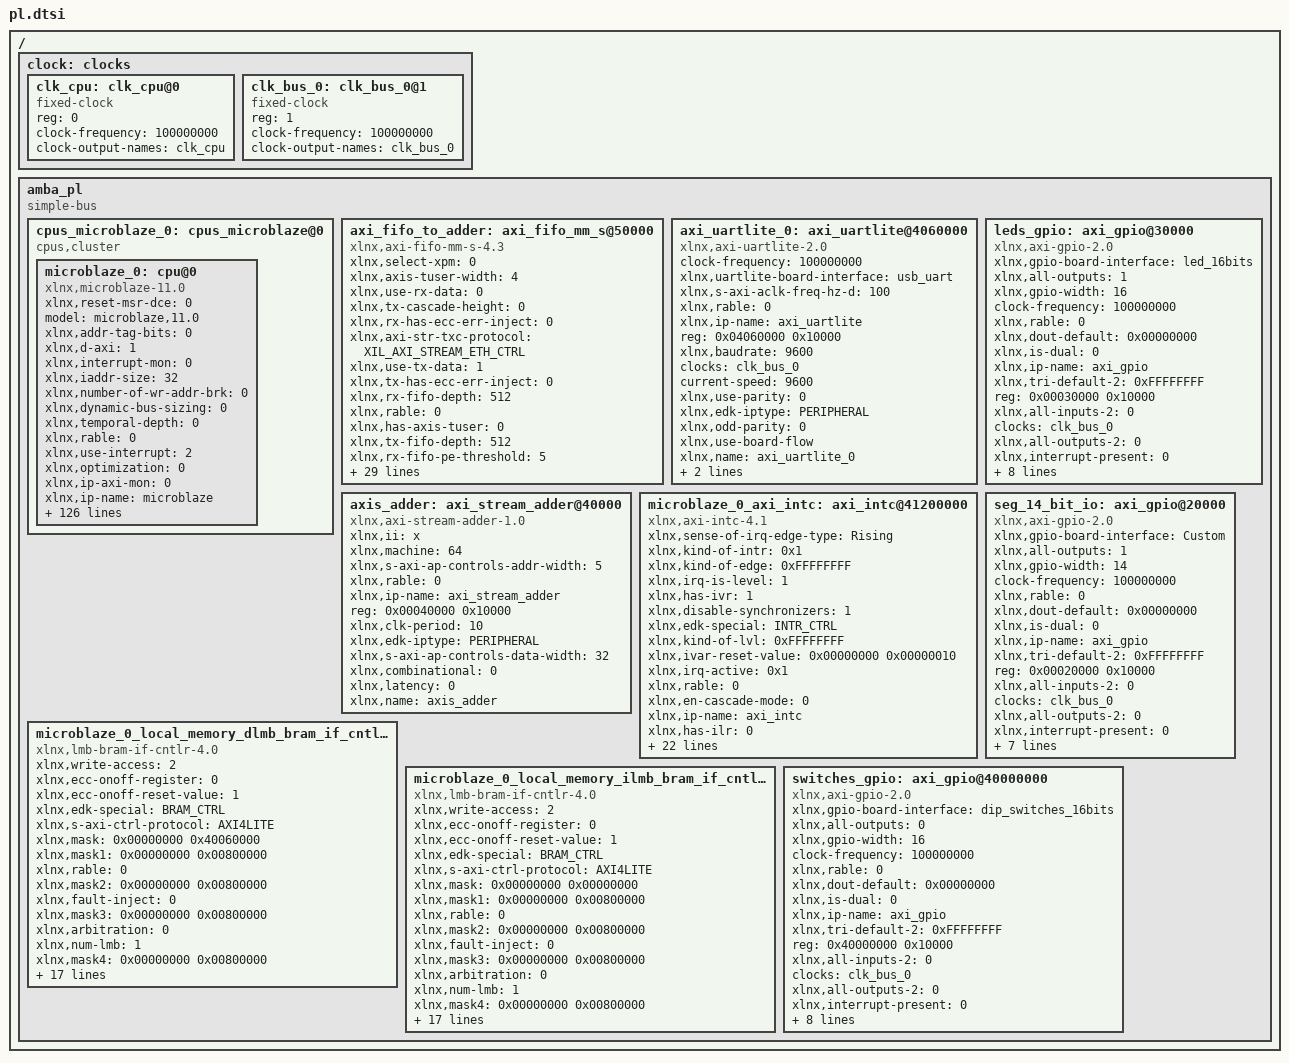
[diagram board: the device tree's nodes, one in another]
/ {
	clock: clocks {
		#address-cells = <1>;
		#size-cells = <0>;
		clk_cpu: clk_cpu@0 {
			compatible = "fixed-clock";
			reg = <0>;
			clock-frequency = <100000000>;
			clock-output-names = "clk_cpu";
			#clock-cells = <0>;
		};
		clk_bus_0: clk_bus_0@1 {
			compatible = "fixed-clock";
			reg = <1>;
			clock-frequency = <100000000>;
			clock-output-names = "clk_bus_0";
			#clock-cells = <0>;
		};
	};
	amba_pl: amba_pl {
		ranges;
		compatible = "simple-bus";
		#address-cells = <1>;
		#size-cells = <1>;
		cpus_microblaze_0: cpus_microblaze@0 {
			#cpu-mask-cells = <1>;
			compatible = "cpus,cluster";
			microblaze_0: cpu@0 {
				xlnx,reset-msr-dce = <0>;
				model = "microblaze,11.0";
				xlnx,addr-tag-bits = <0>;
				xlnx,d-axi = <1>;
				xlnx,interrupt-mon = <0>;
				xlnx,iaddr-size = <32>;
				xlnx,number-of-wr-addr-brk = <0>;
				xlnx,dynamic-bus-sizing = <0>;
				xlnx,temporal-depth = <0>;
				xlnx,rable = <0>;
				xlnx,use-interrupt = <2>;
				xlnx,optimization = <0>;
				xlnx,ip-axi-mon = <0>;
				xlnx,ip-name = "microblaze";
				d-cache-highaddr = <0x3fffffff>;
				xlnx,dcache-force-tag-lutram = <0>;
				xlnx,pc-width = <32>;
				xlnx,interrupt-is-edge = <0>;
				reg = <0x0>;
				xlnx,async-interrupt = <1>;
				xlnx,use-mmu = <0>;
				xlnx,reset-msr-ee = <0>;
				xlnx,icache-victims = <0>;
				xlnx,use-reorder-instr = <1>;
				xlnx,d-lmb-mon = <0>;
				xlnx,d-lmb-protocol = <0>;
				xlnx,ill-opcode-exception = <0>;
				xlnx,dcache-always-used = <1>;
				xlnx,use-div = <0>;
				xlnx,dc-axi-mon = <0>;
				xlnx,debug-trace-async-reset = <0>;
				xlnx,trace = <0>;
				xlnx,part = "xc7a35tcpg236-1";
				i-cache-baseaddr = <0x00000000>;
				xlnx,use-config-reset = <0>;
				xlnx,pvr = <0>;
				xlnx,i-lmb-mon = <0>;
				xlnx,dcache-byte-size = <8192>;
				xlnx,fault-tolerant = <0>;
				xlnx,family = "artix7";
				compatible = "xlnx,microblaze-11.0" , "xlnx,microblaze";
				xlnx,data-size = <32>;
				xlnx,mmu-zones = <16>;
				xlnx,debug-trace-size = <8192>;
				xlnx,mmu-privileged-instr = <0>;
				xlnx,enable-discrete-ports = <0>;
				d-cache-line-size = <16>;
				xlnx,d-lmb = <1>;
				xlnx,sco = <0>;
				xlnx,reset-msr-eip = <0>;
				clock-frequency = <100000000>;
				xlnx,debug-interface = <0>;
				xlnx,use-ext-brk = <0>;
				xlnx,daddr-size = <32>;
				xlnx,debug-enabled = <1>;
				xlnx,reset-msr-ice = <0>;
				xlnx,num-sync-ff-dbg-trace-clk = <2>;
				xlnx,i-lmb-protocol = <0>;
				xlnx,endianness = <1>;
				xlnx,fsl-exception = <0>;
				i-cache-line-size = <16>;
				xlnx,use-extended-fsl-instr = <0>;
				xlnx,reset-msr = <0x00000000>;
				xlnx,dp-axi-mon = <0>;
				xlnx,branch-target-cache-size = <0>;
				xlnx,dcache-use-writeback = <0>;
				xlnx,div-zero-exception = <0>;
				xlnx,mmu-tlb-access = <3>;
				bus-handle = <&amba_pl>;
				xlnx,cache-byte-size = <8192>;
				xlnx,pvr-user2 = <0x00000000>;
				xlnx,opcode-0x0-illegal = <0>;
				xlnx,icache-line-len = <4>;
				xlnx,ecc-use-ce-exception = <0>;
				xlnx,base-vectors = <0x00000000 0x00000000>;
				xlnx,use-dcache = <0>;
				xlnx,use-barrel = <0>;
				xlnx,reset-msr-bip = <0>;
				xlnx,edk-special = "microblaze";
				xlnx,allow-dcache-wr = <1>;
				xlnx,addr-size = <32>;
				xlnx,debug-external-trace = <0>;
				xlnx,piaddr-size = <32>;
				i-cache-highaddr = <0x3fffffff>;
				xlnx,num-sync-ff-clk-debug = <2>;
				xlnx,debug-event-counters = <5>;
				xlnx,fpu-exception = <0>;
				xlnx,allow-icache-wr = <1>;
				xlnx,i-axi = <0>;
				xlnx,g-use-exceptions = <0>;
				xlnx,icache-streams = <0>;
				xlnx,g-template-list = <0>;
				xlnx,dcache-line-len = <4>;
				xlnx,num-sync-ff-clk = <2>;
				xlnx,use-stack-protection = <0>;
				xlnx,use-hw-mul = <0>;
				xlnx,num-sync-ff-dbg-clk = <1>;
				xlnx,interconnect = <2>;
				xlnx,edk-iptype = "PROCESSOR";
				xlnx,debug-latency-counters = <1>;
				i-cache-size = <8192>;
				xlnx,use-fpu = <0>;
				xlnx,reset-msr-ie = <0>;
				xlnx,edge-is-positive = <1>;
				xlnx,use-pcmp-instr = <0>;
				xlnx,use-icache = <0>;
				d-cache-size = <8192>;
				xlnx,async-wakeup = <3>;
				xlnx,use-non-secure = <0>;
				xlnx,dcache-addr-tag = <0>;
				xlnx,number-of-rd-addr-brk = <0>;
				d-cache-baseaddr = <0x00000000>;
				xlnx,area-optimized = <0>;
				xlnx,avoid-primitives = <0>;
				xlnx,lockstep-slave = <0>;
				xlnx,use-ext-nm-brk = <0>;
				xlnx,instr-size = <32>;
				interrupt-handle = <&microblaze_0_axi_intc>;
				xlnx,icache-always-used = <1>;
				xlnx,i-lmb = <1>;
				xlnx,mmu-dtlb-size = <4>;
				xlnx,lockstep-select = <0>;
				xlnx,lmb-data-size = <32>;
				xlnx,ic-axi-mon = <0>;
				xlnx,num-sync-ff-clk-irq = <1>;
				xlnx,fsl-links = <0>;
				timebase-frequency = <100000000>;
				xlnx,icache-force-tag-lutram = <0>;
				xlnx,dcache-data-width = <0>;
				xlnx,dcache-victims = <0>;
				xlnx,use-branch-target-cache = <0>;
				xlnx,debug-profile-size = <0>;
				xlnx,unaligned-exceptions = <0>;
				xlnx,lockstep-master = <0>;
				xlnx,freq = <100000000>;
				xlnx,number-of-pc-brk = <1>;
				xlnx,mmu-itlb-size = <2>;
				xlnx,imprecise-exceptions = <0>;
				xlnx,use-msr-instr = <0>;
				xlnx,icache-data-width = <0>;
				xlnx,debug-counter-width = <32>;
			};
		};
		axi_fifo_to_adder: axi_fifo_mm_s@50000 {
			xlnx,select-xpm = <0>;
			xlnx,axis-tuser-width = <4>;
			compatible = "xlnx,axi-fifo-mm-s-4.3";
			xlnx,use-rx-data = <0>;
			xlnx,tx-cascade-height = <0>;
			xlnx,rx-has-ecc-err-inject = <0>;
			xlnx,axi-str-txc-protocol = "XIL_AXI_STREAM_ETH_CTRL";
			xlnx,use-tx-data = <1>;
			xlnx,tx-has-ecc-err-inject = <0>;
			xlnx,rx-fifo-depth = <512>;
			xlnx,rable = <0>;
			xlnx,has-axis-tuser = <0>;
			xlnx,tx-fifo-depth = <512>;
			xlnx,rx-fifo-pe-threshold = <5>;
			xlnx,data-interface-type = <0>;
			xlnx,ip-name = "axi_fifo_mm_s";
			xlnx,use-tx-ctrl = <0>;
			xlnx,rx-fifo-pf-threshold = <507>;
			xlnx,axis-tid-width = <4>;
			reg = <0x00050000 0x1000>;
			xlnx,tx-fifo-pe-threshold = <5>;
			xlnx,tx-fifo-pf-threshold = <507>;
			xlnx,s-axi4-data-width = <32>;
			xlnx,has-axis-tstrb = <0>;
			xlnx,axi-str-rxd-protocol = "XIL_AXI_STREAM_ETH_DATA";
			xlnx,use-rx-cut-through = <0>;
			xlnx,axi-str-rxd-tdata-width = <32>;
			xlnx,axis-tdest-width = <4>;
			xlnx,has-axis-tkeep = <0>;
			xlnx,has-axis-tid = <0>;
			xlnx,edk-iptype = "PERIPHERAL";
			xlnx,axi-str-txc-tdata-width = <32>;
			xlnx,axi-str-txd-protocol = "XIL_AXI_STREAM_ETH_DATA";
			xlnx,use-tx-cut-through = <0>;
			xlnx,axi-str-txd-tdata-width = <32>;
			xlnx,rx-enable-ecc = <0>;
			status = "okay";
			xlnx,has-axis-tdest = <0>;
			xlnx,tx-enable-ecc = <0>;
			xlnx,s-axi-id-width = <4>;
			xlnx,rx-cascade-height = <0>;
			xlnx,name = "axi_fifo_to_adder";
		};
		axi_uartlite_0: axi_uartlite@4060000 {
			compatible = "xlnx,axi-uartlite-2.0" , "xlnx,xps-uartlite-1.00.a";
			clock-frequency = <100000000>;
			xlnx,uartlite-board-interface = "usb_uart";
			xlnx,s-axi-aclk-freq-hz-d = <100>;
			xlnx,rable = <0>;
			xlnx,ip-name = "axi_uartlite";
			reg = <0x04060000 0x10000>;
			xlnx,baudrate = <9600>;
			clocks = <&clk_bus_0>;
			current-speed = <9600>;
			xlnx,use-parity = <0>;
			xlnx,edk-iptype = "PERIPHERAL";
			xlnx,odd-parity = <0>;
			status = "okay";
			xlnx,use-board-flow;
			xlnx,name = "axi_uartlite_0";
			xlnx,data-bits = <8>;
			xlnx,parity = "No_Parity";
		};
		axis_adder: axi_stream_adder@40000 {
			compatible = "xlnx,axi-stream-adder-1.0";
			xlnx,ii = "x";
			xlnx,machine = <64>;
			xlnx,s-axi-ap-controls-addr-width = <5>;
			xlnx,rable = <0>;
			xlnx,ip-name = "axi_stream_adder";
			reg = <0x00040000 0x10000>;
			xlnx,clk-period = <10>;
			xlnx,edk-iptype = "PERIPHERAL";
			xlnx,s-axi-ap-controls-data-width = <32>;
			status = "okay";
			xlnx,combinational = <0>;
			xlnx,latency = <0>;
			xlnx,name = "axis_adder";
		};
		leds_gpio: axi_gpio@30000 {
			xlnx,gpio-board-interface = "led_16bits";
			compatible = "xlnx,axi-gpio-2.0" , "xlnx,xps-gpio-1.00.a";
			xlnx,all-outputs = <1>;
			xlnx,gpio-width = <16>;
			clock-frequency = <100000000>;
			xlnx,rable = <0>;
			xlnx,dout-default = <0x00000000>;
			xlnx,is-dual = <0>;
			xlnx,ip-name = "axi_gpio";
			xlnx,tri-default-2 = <0xFFFFFFFF>;
			reg = <0x00030000 0x10000>;
			xlnx,all-inputs-2 = <0>;
			clocks = <&clk_bus_0>;
			xlnx,all-outputs-2 = <0>;
			xlnx,interrupt-present = <0>;
			xlnx,gpio2-board-interface = "Custom";
			xlnx,edk-iptype = "PERIPHERAL";
			xlnx,dout-default-2 = <0x00000000>;
			xlnx,gpio2-width = <32>;
			status = "okay";
			clock-names = "s_axi_aclk";
			xlnx,use-board-flow;
			xlnx,tri-default = <0xFFFFFFFF>;
			xlnx,name = "leds_gpio";
			xlnx,all-inputs = <0>;
		};
		microblaze_0_axi_intc: axi_intc@41200000 {
			#interrupt-cells = <2>;
			xlnx,sense-of-irq-edge-type = "Rising";
			xlnx,kind-of-intr = <0x1>;
			xlnx,kind-of-edge = <0xFFFFFFFF>;
			xlnx,irq-is-level = <1>;
			xlnx,has-ivr = <1>;
			compatible = "xlnx,axi-intc-4.1" , "xlnx,xps-intc-1.00.a";
			xlnx,disable-synchronizers = <1>;
			xlnx,edk-special = "INTR_CTRL";
			xlnx,kind-of-lvl = <0xFFFFFFFF>;
			xlnx,ivar-reset-value = <0x00000000 0x00000010>;
			xlnx,irq-active = <0x1>;
			xlnx,rable = <0>;
			xlnx,en-cascade-mode = <0>;
			xlnx,ip-name = "axi_intc";
			xlnx,has-ilr = <0>;
			reg = <0x41200000 0x10000>;
			xlnx,addr-width = <0x20>;
			xlnx,s-axi-aclk-freq-mhz = <100>;
			xlnx,num-sw-intr = <0>;
			xlnx,irq-connection = <0>;
			xlnx,num-intr-inputs = <0x1>;
			xlnx,has-sie = <1>;
			xlnx,has-cie = <1>;
			xlnx,enable-async = <0>;
			xlnx,num-sync-ff = <2>;
			xlnx,mb-clk-not-connected = <1>;
			xlnx,has-ipr = <1>;
			xlnx,edk-iptype = "PERIPHERAL";
			xlnx,sense-of-irq-level-type = "Active_High";
			xlnx,cascade-master = <0>;
			xlnx,processor-clk-freq-mhz = <100>;
			status = "okay";
			xlnx,is-fast = <0x1>;
			xlnx,has-fast = <1>;
			xlnx,ivar-rst-val = <0x0000000000000010>;
			interrupt-controller;
			xlnx,async-intr = <0xFFFFFFFE>;
			xlnx,name = "microblaze_0_axi_intc";
		};
		microblaze_0_local_memory_dlmb_bram_if_cntlr: lmb_bram_if_cntlr@0 {
			xlnx,write-access = <2>;
			compatible = "xlnx,lmb-bram-if-cntlr-4.0";
			xlnx,ecc-onoff-register = <0>;
			xlnx,ecc-onoff-reset-value = <1>;
			xlnx,edk-special = "BRAM_CTRL";
			xlnx,s-axi-ctrl-protocol = "AXI4LITE";
			xlnx,mask = <0x00000000 0x40060000>;
			xlnx,mask1 = <0x00000000 0x00800000>;
			xlnx,rable = <0>;
			xlnx,mask2 = <0x00000000 0x00800000>;
			xlnx,fault-inject = <0>;
			xlnx,mask3 = <0x00000000 0x00800000>;
			xlnx,arbitration = <0>;
			xlnx,num-lmb = <1>;
			xlnx,mask4 = <0x00000000 0x00800000>;
			reg = <0x00000000 0x20000>;
			xlnx,s-axi-ctrl-addr-width = <32>;
			xlnx,mask5 = <0x00000000 0x00800000>;
			xlnx,ecc-status-registers = <0>;
			xlnx,mask6 = <0x00000000 0x00800000>;
			xlnx,lmb-protocol = <0>;
			xlnx,ce-counter-width = <0>;
			xlnx,mask7 = <0x00000000 0x00800000>;
			xlnx,ecc = <0>;
			xlnx,lmb-dwidth = <32>;
			xlnx,interconnect = <0>;
			xlnx,ce-failing-registers = <0>;
			xlnx,edk-iptype = "PERIPHERAL";
			xlnx,ue-failing-registers = <0>;
			xlnx,s-axi-ctrl-data-width = <32>;
			xlnx,bram-awidth = <32>;
			xlnx,lmb-awidth = <32>;
		};
		microblaze_0_local_memory_ilmb_bram_if_cntlr: lmb_bram_if_cntlr@1 {
			xlnx,write-access = <2>;
			compatible = "xlnx,lmb-bram-if-cntlr-4.0";
			xlnx,ecc-onoff-register = <0>;
			xlnx,ecc-onoff-reset-value = <1>;
			xlnx,edk-special = "BRAM_CTRL";
			xlnx,s-axi-ctrl-protocol = "AXI4LITE";
			xlnx,mask = <0x00000000 0x00000000>;
			xlnx,mask1 = <0x00000000 0x00800000>;
			xlnx,rable = <0>;
			xlnx,mask2 = <0x00000000 0x00800000>;
			xlnx,fault-inject = <0>;
			xlnx,mask3 = <0x00000000 0x00800000>;
			xlnx,arbitration = <0>;
			xlnx,num-lmb = <1>;
			xlnx,mask4 = <0x00000000 0x00800000>;
			reg = <0x00000000 0x20000>;
			xlnx,s-axi-ctrl-addr-width = <32>;
			xlnx,mask5 = <0x00000000 0x00800000>;
			xlnx,ecc-status-registers = <0>;
			xlnx,mask6 = <0x00000000 0x00800000>;
			xlnx,lmb-protocol = <0>;
			xlnx,ce-counter-width = <0>;
			xlnx,mask7 = <0x00000000 0x00800000>;
			xlnx,ecc = <0>;
			xlnx,lmb-dwidth = <32>;
			xlnx,interconnect = <0>;
			xlnx,ce-failing-registers = <0>;
			xlnx,edk-iptype = "PERIPHERAL";
			xlnx,ue-failing-registers = <0>;
			xlnx,s-axi-ctrl-data-width = <32>;
			xlnx,bram-awidth = <32>;
			xlnx,lmb-awidth = <32>;
		};
		seg_14_bit_io: axi_gpio@20000 {
			xlnx,gpio-board-interface = "Custom";
			compatible = "xlnx,axi-gpio-2.0" , "xlnx,xps-gpio-1.00.a";
			xlnx,all-outputs = <1>;
			xlnx,gpio-width = <14>;
			clock-frequency = <100000000>;
			xlnx,rable = <0>;
			xlnx,dout-default = <0x00000000>;
			xlnx,is-dual = <0>;
			xlnx,ip-name = "axi_gpio";
			xlnx,tri-default-2 = <0xFFFFFFFF>;
			reg = <0x00020000 0x10000>;
			xlnx,all-inputs-2 = <0>;
			clocks = <&clk_bus_0>;
			xlnx,all-outputs-2 = <0>;
			xlnx,interrupt-present = <0>;
			xlnx,gpio2-board-interface = "Custom";
			xlnx,edk-iptype = "PERIPHERAL";
			xlnx,dout-default-2 = <0x00000000>;
			xlnx,gpio2-width = <32>;
			status = "okay";
			clock-names = "s_axi_aclk";
			xlnx,tri-default = <0xFFFFFFFF>;
			xlnx,name = "seg_14_bit_io";
			xlnx,all-inputs = <0>;
		};
		switches_gpio: axi_gpio@40000000 {
			xlnx,gpio-board-interface = "dip_switches_16bits";
			compatible = "xlnx,axi-gpio-2.0" , "xlnx,xps-gpio-1.00.a";
			xlnx,all-outputs = <0>;
			xlnx,gpio-width = <16>;
			clock-frequency = <100000000>;
			xlnx,rable = <0>;
			xlnx,dout-default = <0x00000000>;
			xlnx,is-dual = <0>;
			xlnx,ip-name = "axi_gpio";
			xlnx,tri-default-2 = <0xFFFFFFFF>;
			reg = <0x40000000 0x10000>;
			xlnx,all-inputs-2 = <0>;
			clocks = <&clk_bus_0>;
			xlnx,all-outputs-2 = <0>;
			xlnx,interrupt-present = <0>;
			xlnx,gpio2-board-interface = "Custom";
			xlnx,edk-iptype = "PERIPHERAL";
			xlnx,dout-default-2 = <0x00000000>;
			xlnx,gpio2-width = <32>;
			status = "okay";
			clock-names = "s_axi_aclk";
			xlnx,use-board-flow;
			xlnx,tri-default = <0xFFFFFFFF>;
			xlnx,name = "switches_gpio";
			xlnx,all-inputs = <1>;
		};
	};
};
